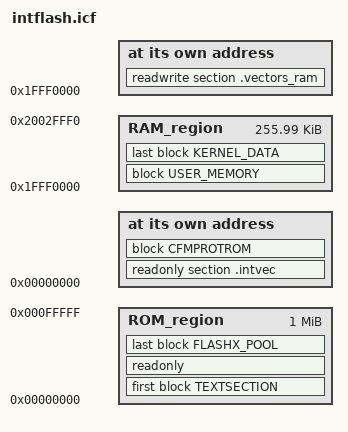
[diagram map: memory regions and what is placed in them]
/*  Конфигурационный файл линкера для платформы на микроконтроллере MK60FN1M0VLQ12 */


//--------------------------------------------------------------
// Определения унаследованные от ICF editor 
//--------------------------------------------------------------
define symbol __ICFEDIT_intvec_start__          = 0x00000000;
define symbol __ICFEDIT_region_ROM_start__      = 0x00000000 ;
define symbol __ICFEDIT_region_ROM_end__        = 0x000FFFFF;
define symbol __ICFEDIT_region_RAM_start__      = 0x1FFF0000;
define symbol __ICFEDIT_region_RAM_end__        = 0x2002FFF0;
define symbol __ICFEDIT_size_cstack__           = 0x400;
define symbol __ICFEDIT_size_heap__             = 0x200;
//--------------------------------------------------------------


define exported symbol __EXTERNAL_MRAM_ROM_BASE = 0x60000000;
define exported symbol __EXTERNAL_MRAM_ROM_SIZE = 0x00060000;
define exported symbol __EXTERNAL_MRAM_RAM_BASE = 0x60060000;
define exported symbol __EXTERNAL_MRAM_RAM_SIZE = 0x00020000;
define exported symbol __EXTERNAL_LCD_BASE      = 0x60000000;
define exported symbol __EXTERNAL_LCD_SIZE      = 0x1FFFF;
define exported symbol __EXTERNAL_LCD_DC_BASE   = 0xA0010000;
define exported symbol __INTERNAL_FLASH_BASE    = 0x00000000;
define exported symbol __INTERNAL_FLASH_SIZE    = 0x00100000;
define exported symbol __INTERNAL_SRAM_BASE     = 0x1FFF0000;
define exported symbol __INTERNAL_SRAM_SIZE     = 0x00020000;
//define exported symbol __UNCACHED_DATA_START    = 0x1FFF0000;
define exported symbol __UNCACHED_DATA_SIZE     = 0x00020000;
define exported symbol __UNCACHED_DATA_END      = 0x2000FFF0;
define exported symbol __SRAM_POOL              = 0x1FFF0000;

define exported symbol __INTERNAL_FLEXNVM_BASE  = 0;
define exported symbol __INTERNAL_FLEXNVM_SIZE  = 0;

define exported symbol __VECTOR_TABLE_ROM_START = 0x00000000;
define exported symbol __VECTOR_TABLE_RAM_START = __ICFEDIT_region_RAM_start__;

define exported symbol __DEFAULT_PROCESSOR_NUMBER = 1;
define exported symbol __DEFAULT_INTERRUPT_STACK_SIZE = 1024;

/* mem_init writes a storeblock_struct at the end of kernel data, max size 32 bytes, so use 0x100 offset */
define exported symbol __BOOT_STACK_ADDRESS = __ICFEDIT_region_RAM_end__ - 0x100;


//--------------------------------------------------------------
// Символы используемые только если определен макрос MQX_ENABLE_USER_MODE 
//--------------------------------------------------------------
define exported symbol __KERNEL_AREA_START = __ICFEDIT_region_RAM_start__;  
define exported symbol __KERNEL_AREA_END = 0x20007FF0;
define exported symbol __USER_AREA_START = 0x20008000;
define exported symbol __USER_AREA_END = __ICFEDIT_region_RAM_end__;
//--------------------------------------------------------------


define exported symbol __KERNEL_DATA_END = __ICFEDIT_region_RAM_end__;

define memory mem with size = 4G;
define region ROM_region   = mem:[from __ICFEDIT_region_ROM_start__   to __ICFEDIT_region_ROM_end__];
define region RAM_region   = mem:[from __ICFEDIT_region_RAM_start__   to __ICFEDIT_region_RAM_end__];


//--------------------------------------------------------------
// Место для размещения _mqx_kernel_data и _mqx_system_stack
//--------------------------------------------------------------
define block KERNEL_DATA with alignment = 8 { section .kernel_data }; 
//--------------------------------------------------------------


//--------------------------------------------------------------
// Блоки используемые только если определен макрос MQX_ENABLE_USER_MODE 
//--------------------------------------------------------------
define block USER_NO_MEMORY with alignment = 32 { section .nouser };
define block USER_RO_MEMORY with alignment = 32 { section .rouser };
define block USER_RW_MEMORY with alignment = 32 { section .rwuser };
//--------------------------------------------------------------

define block USER_DEFAULT_MEMORY with alignment = 32 { readwrite };

//--------------------------------------------------------------
// define block with fixed order - we need fixed order for simplest  MPU settings
//--------------------------------------------------------------
define block USER_MEMORY with fixed order, alignment = 32 { block USER_NO_MEMORY, block USER_RO_MEMORY, block USER_RW_MEMORY, block USER_DEFAULT_MEMORY };


define exported symbol __FLASHX_SECT_SIZE = 0x1000;
define exported symbol __FLASHX_END_ADDR = __INTERNAL_FLASH_BASE + __INTERNAL_FLASH_SIZE; // 0x00000000 + 0x00100000

define block CFMPROTROM with size = 20 { section .cfmconfig };
define block FLASHX_POOL with alignment = __FLASHX_SECT_SIZE { section .flashx };
define block TEXTSECTION with alignment = 4 { section .text };
keep { section .cfmconfig };
keep { section .flashx };

initialize by copy { readwrite };
do not initialize  { section .noinit };
do not initialize  { section .kernel_data };
do not initialize  { section .flashx };

place at address mem:__ICFEDIT_intvec_start__ { readonly section .intvec, block CFMPROTROM };

place in ROM_region { first block TEXTSECTION, readonly,  last block FLASHX_POOL };

place at address mem:__ICFEDIT_region_RAM_start__ { readwrite section .vectors_ram };

//--------------------------------------------------------------
/* each block/segment must be in one line (association to region) because I need kernel data start after other datas */
//--------------------------------------------------------------
place in RAM_region   { block USER_MEMORY, last block KERNEL_DATA };

